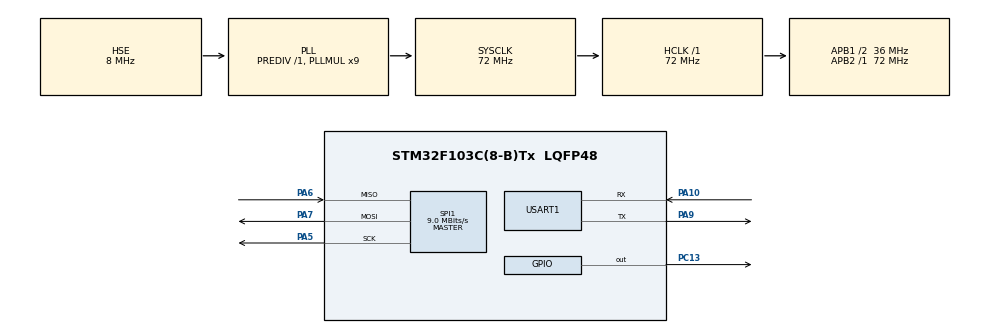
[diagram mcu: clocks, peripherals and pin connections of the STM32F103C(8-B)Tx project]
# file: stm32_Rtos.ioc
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Dma.Request0=SPI1_RX
Dma.Request1=SPI1_TX
Dma.SPI1_RX.0.Direction=DMA_PERIPH_TO_MEMORY
Dma.SPI1_RX.0.Instance=DMA1_Channel2
Dma.SPI1_RX.0.MemDataAlignment=DMA_MDATAALIGN_BYTE
Dma.SPI1_RX.0.MemInc=DMA_MINC_ENABLE
Dma.SPI1_RX.0.Mode=DMA_NORMAL
Dma.SPI1_RX.0.PeriphDataAlignment=DMA_PDATAALIGN_BYTE
Dma.SPI1_RX.0.PeriphInc=DMA_PINC_DISABLE
Dma.SPI1_RX.0.Priority=DMA_PRIORITY_LOW
Dma.SPI1_TX.1.Direction=DMA_MEMORY_TO_PERIPH
Dma.SPI1_TX.1.Instance=DMA1_Channel3
Dma.SPI1_TX.1.MemDataAlignment=DMA_MDATAALIGN_BYTE
Dma.SPI1_TX.1.MemInc=DMA_MINC_ENABLE
Dma.SPI1_TX.1.Mode=DMA_NORMAL
Dma.SPI1_TX.1.PeriphDataAlignment=DMA_PDATAALIGN_BYTE
Dma.SPI1_TX.1.PeriphInc=DMA_PINC_DISABLE
Dma.SPI1_TX.1.Priority=DMA_PRIORITY_LOW
FREERTOS.Tasks01=defaultTask,24,128,StartDefaultTask,Default,NULL,Dynamic,NULL,NULL;Task_PrioHigh,40,128,RtosTask_High,Default,NULL,Dynamic,NULL,NULL;Task_PrioLow,8,128,RtosTask_Low,Default,NULL,Dynamic,NULL,NULL
FREERTOS.Timers01=Task_Timer,task_timer_callback,osTimerPeriodic,Default,NULL,Dynamic,NULL
IWDG.Prescaler=IWDG_PRESCALER_64
IWDG.Reload=625
Mcu.Family=STM32F1
Mcu.Name=STM32F103C(8-B)Tx
Mcu.Package=LQFP48
NVIC.DMA1_Channel2_IRQn=true\:5\:0\:false\:false\:true\:true\:false\:true\:true
NVIC.DMA1_Channel3_IRQn=true\:5\:0\:false\:false\:true\:true\:false\:true\:true
NVIC.PriorityGroup=NVIC_PRIORITYGROUP_4
NVIC.TIM4_IRQn=true\:15\:0\:false\:false\:true\:false\:false\:true\:true
NVIC.TimeBase=TIM4_IRQn
NVIC.TimeBaseIP=TIM4
PA10.Mode=Asynchronous
PA10.Signal=USART1_RX
PA13.Mode=Serial_Wire
PA13.Signal=SYS_JTMS-SWDIO
PA14.Mode=Serial_Wire
PA14.Signal=SYS_JTCK-SWCLK
PA5.Mode=Full_Duplex_Master
PA5.Signal=SPI1_SCK
PA6.Mode=Full_Duplex_Master
PA6.Signal=SPI1_MISO
PA7.Mode=Full_Duplex_Master
PA7.Signal=SPI1_MOSI
PA9.Mode=Asynchronous
PA9.Signal=USART1_TX
PC13-TAMPER-RTC.Signal=GPIO_Output
PD0-OSC_IN.Mode=HSE-External-Oscillator
PD0-OSC_IN.Signal=RCC_OSC_IN
PD1-OSC_OUT.Mode=HSE-External-Oscillator
PD1-OSC_OUT.Signal=RCC_OSC_OUT
ProjectManager.HeapSize=0x200
ProjectManager.StackSize=0x400
ProjectManager.TargetToolchain=MDK-ARM V5
RCC.AHBFreq_Value=72000000
RCC.APB1CLKDivider=RCC_HCLK_DIV2
RCC.APB1Freq_Value=36000000
RCC.APB1TimFreq_Value=72000000
RCC.APB2Freq_Value=72000000
RCC.APB2TimFreq_Value=72000000
RCC.HCLKFreq_Value=72000000
RCC.PLLMUL=RCC_PLL_MUL9
RCC.PLLSourceVirtual=RCC_PLLSOURCE_HSE
RCC.SYSCLKFreq_VALUE=72000000
RCC.SYSCLKSource=RCC_SYSCLKSOURCE_PLLCLK
RCC.USBFreq_Value=72000000
SPI1.BaudRatePrescaler=SPI_BAUDRATEPRESCALER_8
SPI1.CalculateBaudRate=9.0 MBits/s
SPI1.Direction=SPI_DIRECTION_2LINES
SPI1.Mode=SPI_MODE_MASTER
SPI1.VirtualType=VM_MASTER
USART1.VirtualMode=VM_ASYNC
VP_FREERTOS_VS_CMSIS_V2.Mode=CMSIS_V2
VP_IWDG_VS_IWDG.Mode=IWDG_Activate
VP_SYS_VS_tim4.Mode=TIM4
board=custom

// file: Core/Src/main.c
/* USER CODE BEGIN Header */
/**
  ******************************************************************************
  * @file           : main.c
  * @brief          : Main program body
  ******************************************************************************
  * @attention
  *
  * Copyright (c) 2024 STMicroelectronics.
  * All rights reserved.
  *
  * This software is licensed under terms that can be found in the LICENSE file
  * in the root directory of this software component.
  * If no LICENSE file comes with this software, it is provided AS-IS.
  *
  ******************************************************************************
  */
/* USER CODE END Header */
#include "main.h"
#include "cmsis_os.h"
#include "dma.h"
#include "iwdg.h"
#include "spi.h"
#include "usart.h"
#include "gpio.h"

void SystemClock_Config(void);
void MX_FREERTOS_Init(void);

int main(void)
{

  /* MCU Configuration--------------------------------------------------------*/

  /* Reset of all peripherals, Initializes the Flash interface and the Systick. */
  HAL_Init();

  /* Configure the system clock */
  SystemClock_Config();

  /* Initialize all configured peripherals */
  MX_GPIO_Init();
  MX_DMA_Init();
  MX_IWDG_Init();
  MX_USART1_UART_Init();
  MX_SPI1_Init();
  /* USER CODE BEGIN 2 */
  HAL_UART_Transmit(&huart1, (uint8_t*) "Start the program.\n", 19, 10);
  /* USER CODE END 2 */

  /* Init scheduler */
  osKernelInitialize();

  /* Call init function for freertos objects (in cmsis_os2.c) */
  MX_FREERTOS_Init();

  /* Start scheduler */
  osKernelStart();

  /* We should never get here as control is now taken by the scheduler */

  /* Infinite loop */
  while (1)
  {

  }
}

void SystemClock_Config(void)
{
  RCC_OscInitTypeDef RCC_OscInitStruct = {0};
  RCC_ClkInitTypeDef RCC_ClkInitStruct = {0};

  /** Initializes the RCC Oscillators according to the specified parameters
  * in the RCC_OscInitTypeDef structure.
  */
  RCC_OscInitStruct.OscillatorType = RCC_OSCILLATORTYPE_LSI|RCC_OSCILLATORTYPE_HSE;
  RCC_OscInitStruct.HSEState = RCC_HSE_ON;
  RCC_OscInitStruct.HSEPredivValue = RCC_HSE_PREDIV_DIV1;
  RCC_OscInitStruct.HSIState = RCC_HSI_ON;
  RCC_OscInitStruct.LSIState = RCC_LSI_ON;
  RCC_OscInitStruct.PLL.PLLState = RCC_PLL_ON;
  RCC_OscInitStruct.PLL.PLLSource = RCC_PLLSOURCE_HSE;
  RCC_OscInitStruct.PLL.PLLMUL = RCC_PLL_MUL9;
  if (HAL_RCC_OscConfig(&RCC_OscInitStruct) != HAL_OK)
  {
    Error_Handler();
  }

  /** Initializes the CPU, AHB and APB buses clocks
  */
  RCC_ClkInitStruct.ClockType = RCC_CLOCKTYPE_HCLK|RCC_CLOCKTYPE_SYSCLK
                              |RCC_CLOCKTYPE_PCLK1|RCC_CLOCKTYPE_PCLK2;
  RCC_ClkInitStruct.SYSCLKSource = RCC_SYSCLKSOURCE_PLLCLK;
  RCC_ClkInitStruct.AHBCLKDivider = RCC_SYSCLK_DIV1;
  RCC_ClkInitStruct.APB1CLKDivider = RCC_HCLK_DIV2;
  RCC_ClkInitStruct.APB2CLKDivider = RCC_HCLK_DIV1;

  if (HAL_RCC_ClockConfig(&RCC_ClkInitStruct, FLASH_LATENCY_2) != HAL_OK)
  {
    Error_Handler();
  }
}

void HAL_TIM_PeriodElapsedCallback(TIM_HandleTypeDef *htim)
{
  if (htim->Instance == TIM4)
  {
    HAL_IncTick();
  }
}

void Error_Handler(void)
{
  __disable_irq();
  while (1)
  {
  }
}

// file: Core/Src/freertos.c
/* USER CODE BEGIN Header */
/**
  ******************************************************************************
  * File Name          : freertos.c
  * Description        : Code for freertos applications
  ******************************************************************************
  * @attention
  *
  * Copyright (c) 2024 STMicroelectronics.
  * All rights reserved.
  *
  * This software is licensed under terms that can be found in the LICENSE file
  * in the root directory of this software component.
  * If no LICENSE file comes with this software, it is provided AS-IS.
  *
  ******************************************************************************
  */
/* USER CODE END Header */

#include "FreeRTOS.h"
#include "task.h"
#include "main.h"
#include "cmsis_os.h"

/* USER CODE BEGIN Includes */
#include "iwdg.h"
#include "Os_Cyclic.h"
/* USER CODE END Includes */

/* Definitions for defaultTask */
osThreadId_t defaultTaskHandle;
const osThreadAttr_t defaultTask_attributes = {
  .name = "defaultTask",
  .stack_size = 128 * 4,
  .priority = (osPriority_t) osPriorityNormal,
};
/* Definitions for Task_PrioHigh */
osThreadId_t Task_PrioHighHandle;
const osThreadAttr_t Task_PrioHigh_attributes = {
  .name = "Task_PrioHigh",
  .stack_size = 128 * 4,
  .priority = (osPriority_t) osPriorityHigh,
};
/* Definitions for Task_PrioLow */
osThreadId_t Task_PrioLowHandle;
const osThreadAttr_t Task_PrioLow_attributes = {
  .name = "Task_PrioLow",
  .stack_size = 128 * 4,
  .priority = (osPriority_t) osPriorityNormal,
};
/* Definitions for Task_Timer */
osTimerId_t Task_TimerHandle;
const osTimerAttr_t Task_Timer_attributes = {
  .name = "Task_Timer"
};

void StartDefaultTask(void *argument);
void RtosTask_High(void *argument);
void RtosTask_Low(void *argument);
void task_timer_callback(void *argument);

void MX_FREERTOS_Init(void); /* (MISRA C 2004 rule 8.1) */

void MX_FREERTOS_Init(void) {

  /* Create the timer(s) */
  /* creation of Task_Timer */
  Task_TimerHandle = osTimerNew(task_timer_callback, osTimerPeriodic, NULL, &Task_Timer_attributes);

  /* Create the thread(s) */
  /* creation of defaultTask */
  defaultTaskHandle = osThreadNew(StartDefaultTask, NULL, &defaultTask_attributes);

  /* creation of Task_PrioHigh */
  Task_PrioHighHandle = osThreadNew(RtosTask_High, NULL, &Task_PrioHigh_attributes);

  /* creation of Task_PrioLow */
  Task_PrioLowHandle = osThreadNew(RtosTask_Low, NULL, &Task_PrioLow_attributes);

}

void StartDefaultTask(void *argument)
{
  for(;;)
  {
    osDelay(1);
  }
}

void RtosTask_High(void *argument)
{
  /* USER CODE BEGIN RtosTask_High */
  HAL_IWDG_Refresh(&hiwdg);
  /* Infinite loop */
  for(;;)
  {
    Os_Cyclic_HighPriTask();
    HAL_IWDG_Refresh(&hiwdg);
    osDelay(1);
  }
  /* USER CODE END RtosTask_High */
}

void RtosTask_Low(void *argument)
{
  /* USER CODE BEGIN RtosTask_Low */
  /* Infinite loop */
  for(;;)
  {
    Os_Cyclic_LowPriTask();
    HAL_IWDG_Refresh(&hiwdg);
    osDelay(1);
  }
  /* USER CODE END RtosTask_Low */
}

/* task_timer_callback function */
void task_timer_callback(void *argument)
{
}
